# PIC32MZ2048EFM144 register map
Registers are 32-bit, access not given, reset 0x0 unless marked. A register's access mark holds for its fields unless they carry their own. Offsets are from the block's base; [hi:lo] are bit positions; 'fields as' and 'values as' point back to an identical list.

## ETH — ETH peripheral
Base 0xBF882000
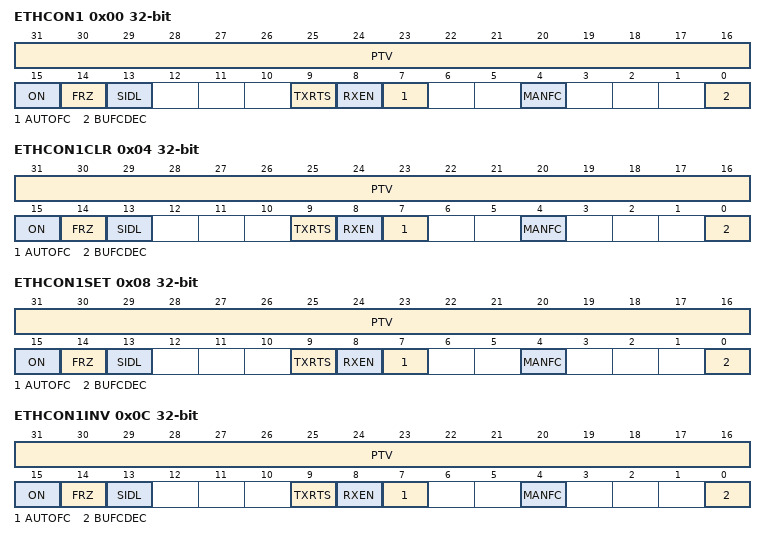
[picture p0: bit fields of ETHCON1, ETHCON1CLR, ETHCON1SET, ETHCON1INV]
0x00 ETHCON1
  [31:16] PTV, [15] ON, [14] FRZ, [13] SIDL, [9] TXRTS, [8] RXEN, [7] AUTOFC, [4] MANFC, [0] BUFCDEC
0x04 ETHCON1CLR
  fields as ETHCON1
0x08 ETHCON1SET
  fields as ETHCON1
0x0C ETHCON1INV
  fields as ETHCON1
0x10 ETHCON2
  [10:4] RXBUF_SZ
0x14 ETHCON2CLR
  [10:4] RXBUF_SZ
0x18 ETHCON2SET
  [10:4] RXBUF_SZ
0x1C ETHCON2INV
  [10:4] RXBUF_SZ
0x20 ETHTXST
  [31:2] TXSTADDR
0x24 ETHTXSTCLR
  [31:2] TXSTADDR
0x28 ETHTXSTSET
  [31:2] TXSTADDR
0x2C ETHTXSTINV
  [31:2] TXSTADDR
0x30 ETHRXST
  [31:2] RXSTADDR
0x34 ETHRXSTCLR
  [31:2] RXSTADDR
0x38 ETHRXSTSET
  [31:2] RXSTADDR
0x3C ETHRXSTINV
  [31:2] RXSTADDR
0x40 ETHHT0
  [31:0] HT
0x44 ETHHT0CLR
  [31:0] HT
0x48 ETHHT0SET
  [31:0] HT
0x4C ETHHT0INV
  [31:0] HT
0x50 ETHHT1
  [31:0] HT
0x54 ETHHT1CLR
  [31:0] HT
0x58 ETHHT1SET
  [31:0] HT
0x5C ETHHT1INV
  [31:0] HT
0x60 ETHPMM0
  [31:0] PMM
0x64 ETHPMM0CLR
  [31:0] PMM
0x68 ETHPMM0SET
  [31:0] PMM
0x6C ETHPMM0INV
  [31:0] PMM
0x70 ETHPMM1
  [31:0] PMM
0x74 ETHPMM1CLR
  [31:0] PMM
0x78 ETHPMM1SET
  [31:0] PMM
0x7C ETHPMM1INV
  [31:0] PMM
0x80 ETHPMCS
  [15:0] PMCS
0x84 ETHPMCSCLR
  [15:0] PMCS
0x88 ETHPMCSSET
  [15:0] PMCS
0x8C ETHPMCSINV
  [15:0] PMCS
0x90 ETHPMO
  [15:0] PMO
0x94 ETHPMOCLR
  [15:0] PMO
0x98 ETHPMOSET
  [15:0] PMO
0x9C ETHPMOINV
  [15:0] PMO
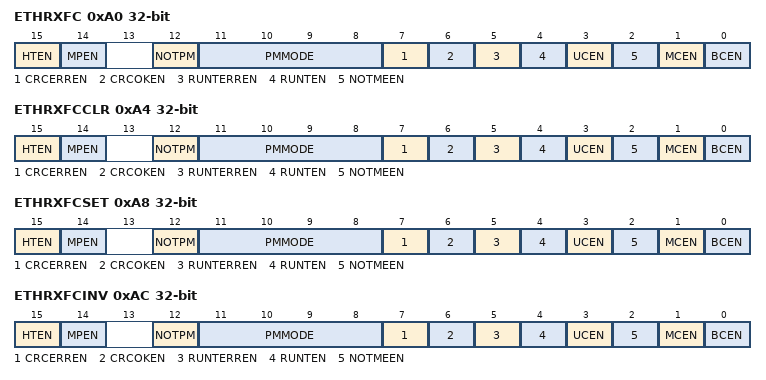
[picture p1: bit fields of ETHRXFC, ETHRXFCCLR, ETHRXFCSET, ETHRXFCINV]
0xA0 ETHRXFC
  [15] HTEN, [14] MPEN, [12] NOTPM, [11:8] PMMODE, [7] CRCERREN, [6] CRCOKEN, [5] RUNTERREN, [4] RUNTEN, [3] UCEN, [2] NOTMEEN, [1] MCEN, [0] BCEN
0xA4 ETHRXFCCLR
  fields as ETHRXFC
0xA8 ETHRXFCSET
  fields as ETHRXFC
0xAC ETHRXFCINV
  fields as ETHRXFC
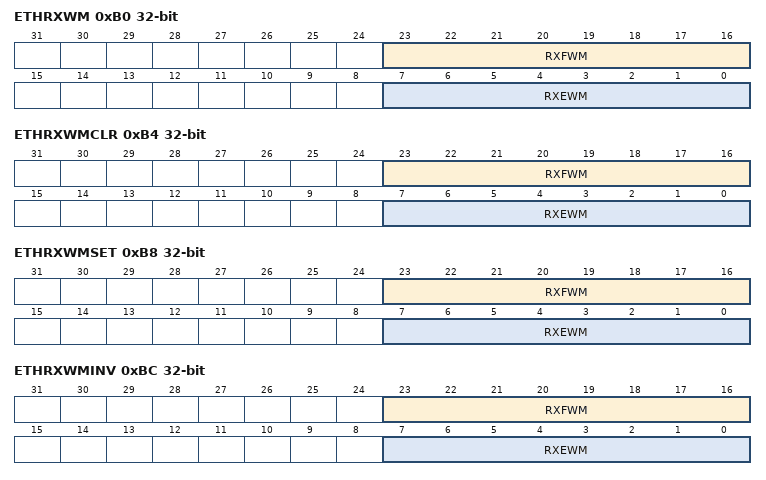
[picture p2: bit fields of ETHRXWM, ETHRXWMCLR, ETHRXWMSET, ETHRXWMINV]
0xB0 ETHRXWM
  [23:16] RXFWM, [7:0] RXEWM
0xB4 ETHRXWMCLR
  [23:16] RXFWM, [7:0] RXEWM
0xB8 ETHRXWMSET
  [23:16] RXFWM, [7:0] RXEWM
0xBC ETHRXWMINV
  [23:16] RXFWM, [7:0] RXEWM
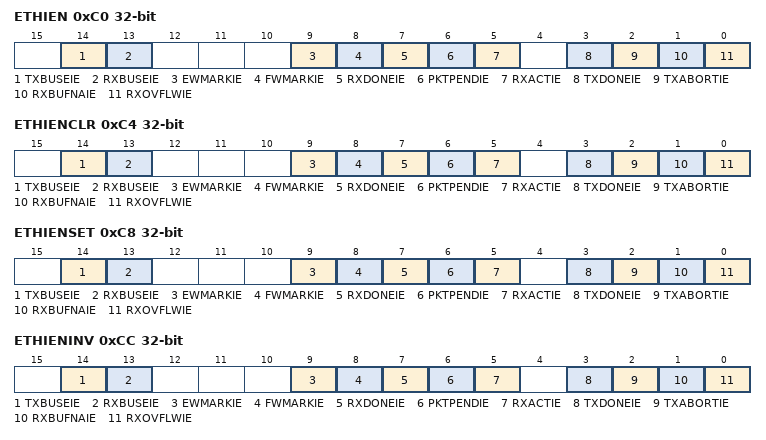
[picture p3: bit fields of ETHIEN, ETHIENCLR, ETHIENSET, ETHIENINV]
0xC0 ETHIEN
  [14] TXBUSEIE, [13] RXBUSEIE, [9] EWMARKIE, [8] FWMARKIE, [7] RXDONEIE, [6] PKTPENDIE, [5] RXACTIE, [3] TXDONEIE, [2] TXABORTIE, [1] RXBUFNAIE, [0] RXOVFLWIE
0xC4 ETHIENCLR
  fields as ETHIEN
0xC8 ETHIENSET
  fields as ETHIEN
0xCC ETHIENINV
  fields as ETHIEN
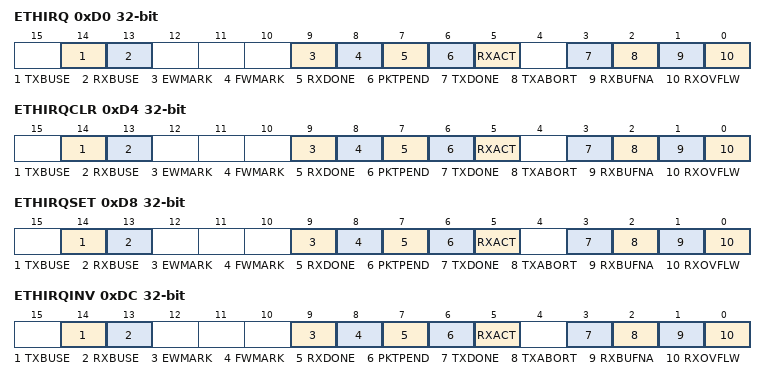
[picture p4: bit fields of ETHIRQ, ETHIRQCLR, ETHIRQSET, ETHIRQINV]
0xD0 ETHIRQ
  [14] TXBUSE, [13] RXBUSE, [9] EWMARK, [8] FWMARK, [7] RXDONE, [6] PKTPEND, [5] RXACT, [3] TXDONE, [2] TXABORT, [1] RXBUFNA, [0] RXOVFLW
0xD4 ETHIRQCLR
  fields as ETHIRQ
0xD8 ETHIRQSET
  fields as ETHIRQ
0xDC ETHIRQINV
  fields as ETHIRQ
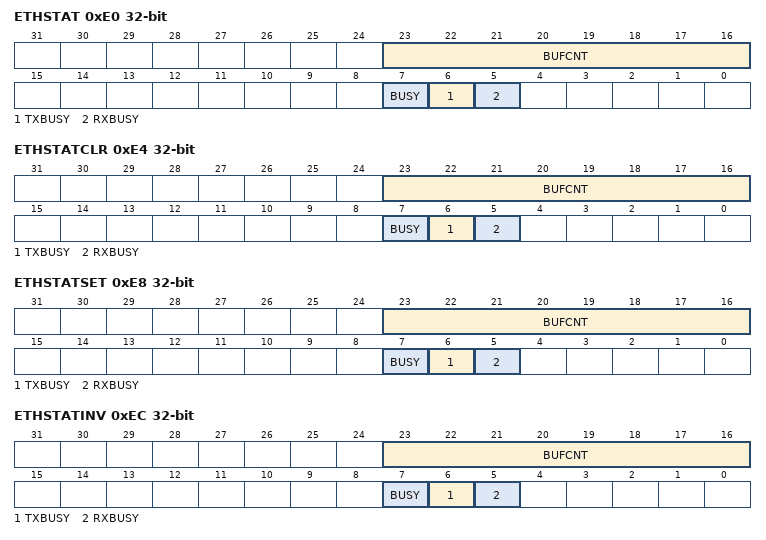
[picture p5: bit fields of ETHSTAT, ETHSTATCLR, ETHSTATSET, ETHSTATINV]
0xE0 ETHSTAT
  [23:16] BUFCNT, [7] BUSY, [6] TXBUSY, [5] RXBUSY
0xE4 ETHSTATCLR
  [23:16] BUFCNT, [7] BUSY, [6] TXBUSY, [5] RXBUSY
0xE8 ETHSTATSET
  [23:16] BUFCNT, [7] BUSY, [6] TXBUSY, [5] RXBUSY
0xEC ETHSTATINV
  [23:16] BUFCNT, [7] BUSY, [6] TXBUSY, [5] RXBUSY
0x100 RXOVFLOW
  [15:0] RXOVFLWCNT
0x104 RXOVFLOWCLR
  [15:0] RXOVFLWCNT
0x108 RXOVFLOWSET
  [15:0] RXOVFLWCNT
0x10C RXOVFLOWINV
  [15:0] RXOVFLWCNT
0x110 ETHFRMTXOK
  [15:0] FRMTXOKCNT
0x114 ETHFRMTXOKCLR
  [15:0] FRMTXOKCNT
0x118 ETHFRMTXOKSET
  [15:0] FRMTXOKCNT
0x11C ETHFRMTXOKINV
  [15:0] FRMTXOKCNT
0x120 ETHSCOLFRM
  [15:0] SCOLFRMCNT
0x124 ETHSCOLFRMCLR
  [15:0] SCOLFRMCNT
0x128 ETHSCOLFRMSET
  [15:0] SCOLFRMCNT
0x12C ETHSCOLFRMINV
  [15:0] SCOLFRMCNT
0x130 ETHMCOLFRM
  [15:0] MCOLFRMCNT
0x134 ETHMCOLFRMCLR
  [15:0] MCOLFRMCNT
0x138 ETHMCOLFRMSET
  [15:0] MCOLFRMCNT
0x13C ETHMCOLFRMINV
  [15:0] MCOLFRMCNT
0x140 ETHFRMRXOK
  [15:0] FRMRXOKCNT
0x144 ETHFRMRXOKCLR
  [15:0] FRMRXOKCNT
0x148 ETHFRMRXOKSET
  [15:0] FRMRXOKCNT
0x14C ETHFRMRXOKINV
  [15:0] FRMRXOKCNT
0x150 ETHFCSERR
  [15:0] FCSERRCNT
0x154 ETHFCSERRCLR
  [15:0] FCSERRCNT
0x158 ETHFCSERRSET
  [15:0] FCSERRCNT
0x15C ETHFCSERRINV
  [15:0] FCSERRCNT
0x160 ETHALGNERR
  [15:0] ALGNERRCNT
0x164 ETHALGNERRCLR
  [15:0] ALGNERRCNT
0x168 ETHALGNERRSET
  [15:0] ALGNERRCNT
0x16C ETHALGNERRINV
  [15:0] ALGNERRCNT
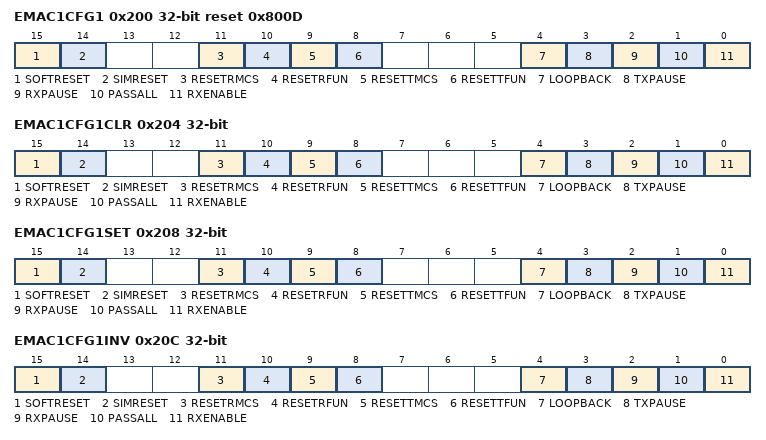
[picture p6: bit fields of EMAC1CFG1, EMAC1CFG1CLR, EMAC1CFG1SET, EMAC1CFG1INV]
0x200 EMAC1CFG1 reset 0x800D
  [15] SOFTRESET, [14] SIMRESET, [11] RESETRMCS, [10] RESETRFUN, [9] RESETTMCS, [8] RESETTFUN, [4] LOOPBACK, [3] TXPAUSE, [2] RXPAUSE, [1] PASSALL, [0] RXENABLE
0x204 EMAC1CFG1CLR
  fields as EMAC1CFG1
0x208 EMAC1CFG1SET
  fields as EMAC1CFG1
0x20C EMAC1CFG1INV
  fields as EMAC1CFG1
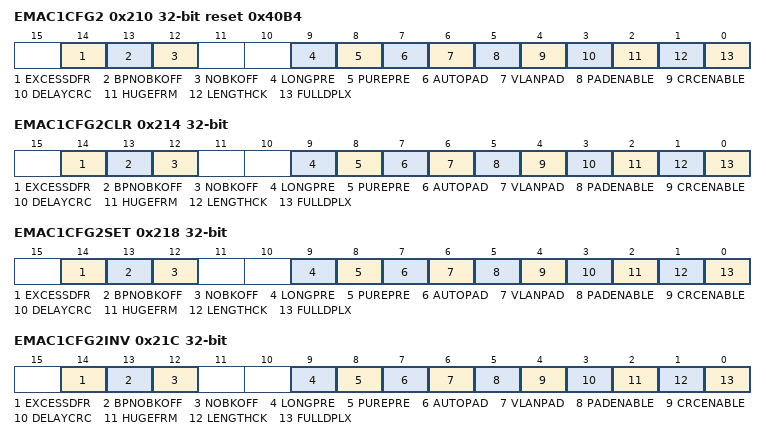
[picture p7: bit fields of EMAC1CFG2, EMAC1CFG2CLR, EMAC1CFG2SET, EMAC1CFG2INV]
0x210 EMAC1CFG2 reset 0x40B4
  [14] EXCESSDFR, [13] BPNOBKOFF, [12] NOBKOFF, [9] LONGPRE, [8] PUREPRE, [7] AUTOPAD, [6] VLANPAD, [5] PADENABLE, [4] CRCENABLE, [3] DELAYCRC, [2] HUGEFRM, [1] LENGTHCK, [0] FULLDPLX
0x214 EMAC1CFG2CLR
  fields as EMAC1CFG2
0x218 EMAC1CFG2SET
  fields as EMAC1CFG2
0x21C EMAC1CFG2INV
  fields as EMAC1CFG2
0x220 EMAC1IPGT reset 0x12
  [6:0] B2BIPKTGP
0x224 EMAC1IPGTCLR
  [6:0] B2BIPKTGP
0x228 EMAC1IPGTSET
  [6:0] B2BIPKTGP
0x22C EMAC1IPGTINV
  [6:0] B2BIPKTGP
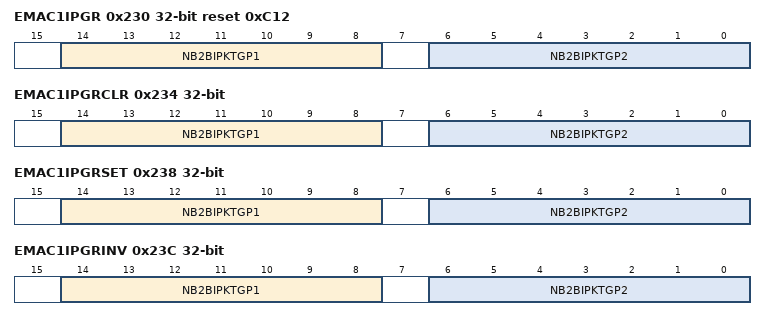
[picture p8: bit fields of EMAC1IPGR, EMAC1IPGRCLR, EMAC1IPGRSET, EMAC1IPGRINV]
0x230 EMAC1IPGR reset 0xC12
  [14:8] NB2BIPKTGP1, [6:0] NB2BIPKTGP2
0x234 EMAC1IPGRCLR
  [14:8] NB2BIPKTGP1, [6:0] NB2BIPKTGP2
0x238 EMAC1IPGRSET
  [14:8] NB2BIPKTGP1, [6:0] NB2BIPKTGP2
0x23C EMAC1IPGRINV
  [14:8] NB2BIPKTGP1, [6:0] NB2BIPKTGP2
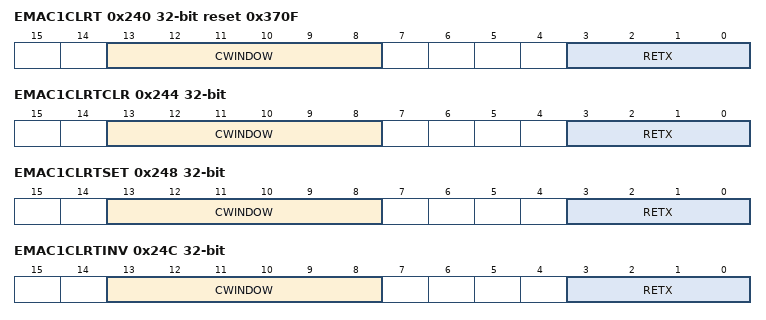
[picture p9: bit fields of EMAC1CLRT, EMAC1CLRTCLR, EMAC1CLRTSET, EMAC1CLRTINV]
0x240 EMAC1CLRT reset 0x370F
  [13:8] CWINDOW, [3:0] RETX
0x244 EMAC1CLRTCLR
  [13:8] CWINDOW, [3:0] RETX
0x248 EMAC1CLRTSET
  [13:8] CWINDOW, [3:0] RETX
0x24C EMAC1CLRTINV
  [13:8] CWINDOW, [3:0] RETX
0x250 EMAC1MAXF reset 0x5EE
  [15:0] MACMAXF
0x254 EMAC1MAXFCLR
  [15:0] MACMAXF
0x258 EMAC1MAXFSET
  [15:0] MACMAXF
0x25C EMAC1MAXFINV
  [15:0] MACMAXF
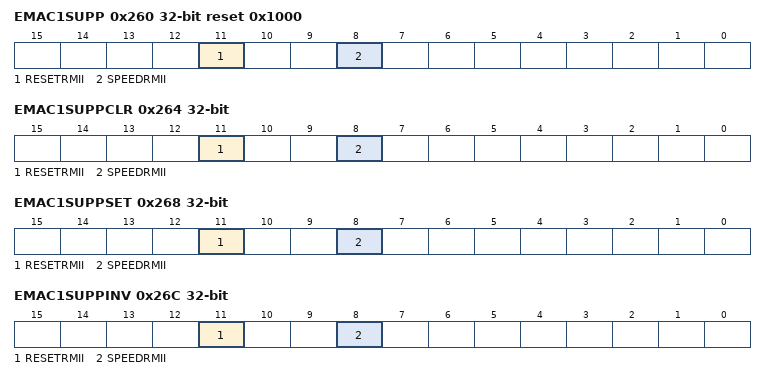
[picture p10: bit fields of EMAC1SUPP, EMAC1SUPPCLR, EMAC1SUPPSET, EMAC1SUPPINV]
0x260 EMAC1SUPP reset 0x1000
  [11] RESETRMII, [8] SPEEDRMII
0x264 EMAC1SUPPCLR
  [11] RESETRMII, [8] SPEEDRMII
0x268 EMAC1SUPPSET
  [11] RESETRMII, [8] SPEEDRMII
0x26C EMAC1SUPPINV
  [11] RESETRMII, [8] SPEEDRMII
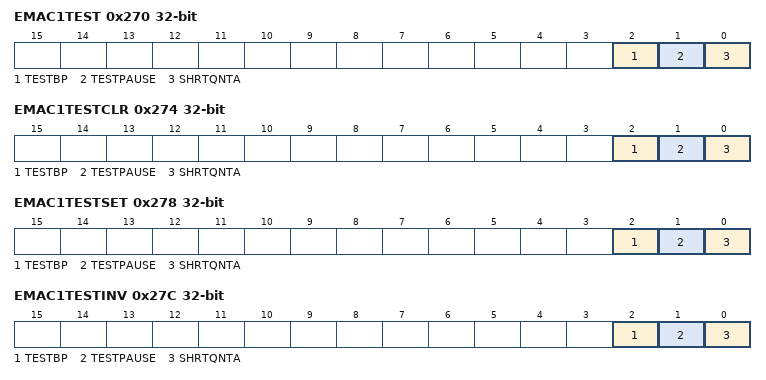
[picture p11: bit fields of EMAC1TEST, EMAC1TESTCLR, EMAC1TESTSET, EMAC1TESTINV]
0x270 EMAC1TEST
  [2] TESTBP, [1] TESTPAUSE, [0] SHRTQNTA
0x274 EMAC1TESTCLR
  [2] TESTBP, [1] TESTPAUSE, [0] SHRTQNTA
0x278 EMAC1TESTSET
  [2] TESTBP, [1] TESTPAUSE, [0] SHRTQNTA
0x27C EMAC1TESTINV
  [2] TESTBP, [1] TESTPAUSE, [0] SHRTQNTA
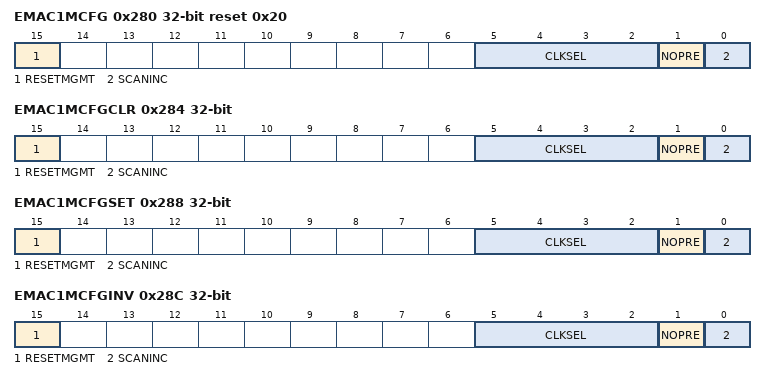
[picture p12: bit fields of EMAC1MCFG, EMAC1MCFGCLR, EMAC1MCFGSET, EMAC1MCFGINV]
0x280 EMAC1MCFG reset 0x20
  [15] RESETMGMT, [5:2] CLKSEL, [1] NOPRE, [0] SCANINC
0x284 EMAC1MCFGCLR
  [15] RESETMGMT, [5:2] CLKSEL, [1] NOPRE, [0] SCANINC
0x288 EMAC1MCFGSET
  [15] RESETMGMT, [5:2] CLKSEL, [1] NOPRE, [0] SCANINC
0x28C EMAC1MCFGINV
  [15] RESETMGMT, [5:2] CLKSEL, [1] NOPRE, [0] SCANINC
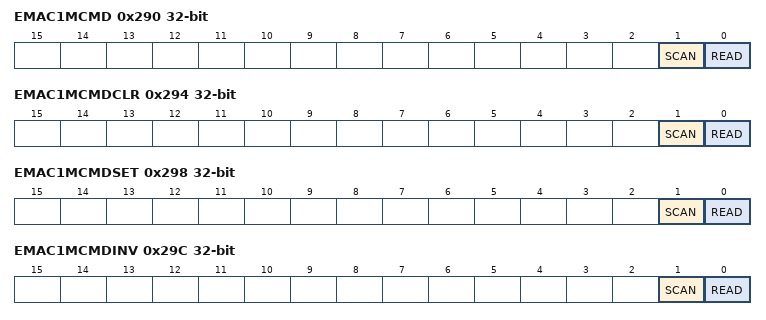
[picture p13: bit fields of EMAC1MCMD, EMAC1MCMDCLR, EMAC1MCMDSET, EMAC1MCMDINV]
0x290 EMAC1MCMD
  [1] SCAN, [0] READ
0x294 EMAC1MCMDCLR
  [1] SCAN, [0] READ
0x298 EMAC1MCMDSET
  [1] SCAN, [0] READ
0x29C EMAC1MCMDINV
  [1] SCAN, [0] READ
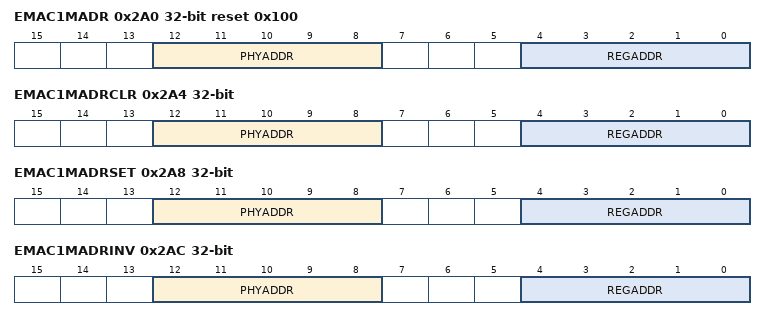
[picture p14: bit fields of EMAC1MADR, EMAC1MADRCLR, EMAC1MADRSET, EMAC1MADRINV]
0x2A0 EMAC1MADR reset 0x100
  [12:8] PHYADDR, [4:0] REGADDR
0x2A4 EMAC1MADRCLR
  [12:8] PHYADDR, [4:0] REGADDR
0x2A8 EMAC1MADRSET
  [12:8] PHYADDR, [4:0] REGADDR
0x2AC EMAC1MADRINV
  [12:8] PHYADDR, [4:0] REGADDR
0x2B0 EMAC1MWTD
  [15:0] MWTD
0x2B4 EMAC1MWTDCLR
  [15:0] MWTD
0x2B8 EMAC1MWTDSET
  [15:0] MWTD
0x2BC EMAC1MWTDINV
  [15:0] MWTD
0x2C0 EMAC1MRDD
  [15:0] MRDD
0x2C4 EMAC1MRDDCLR
  [15:0] MRDD
0x2C8 EMAC1MRDDSET
  [15:0] MRDD
0x2CC EMAC1MRDDINV
  [15:0] MRDD
0x2D0 EMAC1MIND
  [3] LINKFAIL, [2] NOTVALID, [1] SCAN, [0] MIIMBUSY
0x2D4 EMAC1MINDCLR
  [3] LINKFAIL, [2] NOTVALID, [1] SCAN, [0] MIIMBUSY
0x2D8 EMAC1MINDSET
  [3] LINKFAIL, [2] NOTVALID, [1] SCAN, [0] MIIMBUSY
0x2DC EMAC1MINDINV
  [3] LINKFAIL, [2] NOTVALID, [1] SCAN, [0] MIIMBUSY
0x300 EMAC1SA0
  [15:8] STNADDR6, [7:0] STNADDR5
0x304 EMAC1SA0CLR
  [15:8] STNADDR6, [7:0] STNADDR5
0x308 EMAC1SA0SET
  [15:8] STNADDR6, [7:0] STNADDR5
0x30C EMAC1SA0INV
  [15:8] STNADDR6, [7:0] STNADDR5
0x310 EMAC1SA1
  [15:8] STNADDR4, [7:0] STNADDR3
0x314 EMAC1SA1CLR
  [15:8] STNADDR4, [7:0] STNADDR3
0x318 EMAC1SA1SET
  [15:8] STNADDR4, [7:0] STNADDR3
0x31C EMAC1SA1INV
  [15:8] STNADDR4, [7:0] STNADDR3
0x320 EMAC1SA2
  [15:8] STNADDR2, [7:0] STNADDR1
0x324 EMAC1SA2CLR
  [15:8] STNADDR2, [7:0] STNADDR1
0x328 EMAC1SA2SET
  [15:8] STNADDR2, [7:0] STNADDR1
0x32C EMAC1SA2INV
  [15:8] STNADDR2, [7:0] STNADDR1
